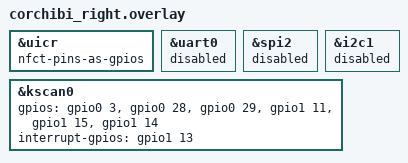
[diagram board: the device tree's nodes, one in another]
#include "corchibi.dtsi"

&uicr {
    nfct-pins-as-gpios;
};

/* 最新版の仕様に合わせて不要な通信機能を停止 */
&uart0 { status = "disabled"; };
&spi2 { status = "disabled"; };
&i2c1 { status = "disabled"; };

&kscan0 {
    /* 物理ピン番号での直接指定で確実に割り当てます */
    gpios
        = <&gpio0 3 GPIO_ACTIVE_HIGH>  // D1 (P0.03)
        , <&gpio0 28 GPIO_ACTIVE_HIGH> // D2 (P0.28)
        , <&gpio0 29 GPIO_ACTIVE_HIGH> // D3 (P0.29)
        , <&gpio1 11 GPIO_ACTIVE_HIGH> // D6 (P1.11)
        , <&gpio1 15 GPIO_ACTIVE_HIGH> // D10 (P1.15)
        , <&gpio1 14 GPIO_ACTIVE_HIGH> // D9 (P1.14)
        ;
    /* スリープ復帰用の割り込みピンも直接指定で復活させます */
    interrupt-gpios = <&gpio1 13 (GPIO_ACTIVE_HIGH | GPIO_PULL_DOWN)>; // D8 (P1.13)
};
